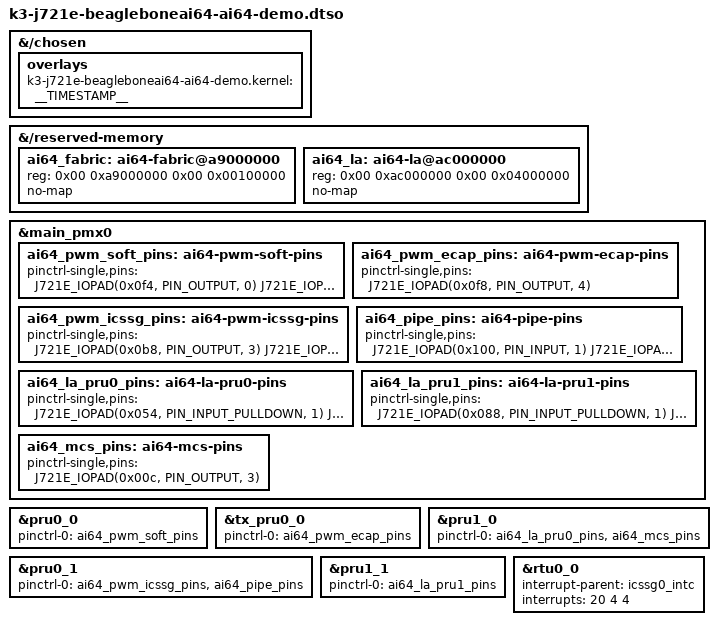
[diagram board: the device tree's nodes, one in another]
// SPDX-License-Identifier: MIT
// BeagleBone AI-64 demo: the ICSSG pins, the vring IRQ of ICSSG0 RTU0 (the
// RTU with RPMsg), and the DDR the cores use to talk to each other.
//
//   ICSSG0 slice 0, PWM in software (pru/pwm):
//     PRU0  P8.11  AB24  pad 0x0f4  mode 0  PRG0_PRU0_GPO17, output A
//     PRU0  P8.12  AH28  pad 0x0f0  mode 0  PRG0_PRU0_GPO16, output B
//     Tx_PRU0  P8.15  AB29  pad 0x0f8  mode 4  PRG0_ECAP0_IN_APWM_OUT, A's copy
//   ICSSG0 slice 1, the ICSSG's PWM module (pru/pwm):
//     PRU1  P9.12  AE27  pad 0x0b8  mode 3  PRG0_PWM2_A0, output A
//     PRU1  P9.15  AD25  pad 0x0c0  mode 3  PRG0_PWM2_B0, output B
//     PRU1  P8.31  AE29  pad 0x100  mode 1  PRG0_PRU1_GPI0, the pipeline's
//           input (zephyr/include/ai64_pipe.h); P8.31's other ball, AJ25
//           (pad 0x084), is held off: mode 7, transmit disabled
//   ICSSG1, the logic analyzer (pru/logic_analyzer): 19 inputs, each mode 1,
//     PRG1_PRU<n>_GPI<bit>, with its pull-down on (zephyr/include/ai64_la.h):
//     PRU0  P8.03 P8.07 P8.08 P8.09 P8.10 P8.36 P8.38 P9.11 P9.13 P9.23
//     PRU1  P8.05 P8.06 P8.21 P8.23 P8.25 P8.32 P8.33 P8.35 P9.21
//     P8.32, P8.33, P8.35, P8.38, and P9.21 have a second ball, held off
//   ICSSG1, the multicore scheduler (extra-demos/icssg1-multicore-scheduler):
//     all six cores  P8.17  AF22  pad 0x00c  mode 3  PRG1_PWM2_A0
//   The other header pins have one ball each.
//
// Zephyr muxes its own pins (UART2 on P8.34/P8.22, SPI7 on P9.28/P9.30/
// P9.31, EHRPWM4_B on P9.25) from its devicetree. They are not in this
// overlay. PINMUX.md lists every pin the demo uses.
//
// This overlay replaces k3-j721e-beagleboneai64-pwm-epwm4-p9_25.dtbo, which
// gives EHRPWM4 and the W26 ball to Linux; in this demo Zephyr owns both.
// install-beagle.sh drops that one from the boot entry.

/dts-v1/;
/plugin/;

#include "ti/k3-pinctrl.h"

&{/chosen} {
	overlays {
		k3-j721e-beagleboneai64-ai64-demo.kernel = __TIMESTAMP__;
	};
};

/*
 * The fabric (zephyr/include/ai64_fabric.h): every demo core's inbox, in
 * the 16 MiB gap between the C7x's carveout and the IPC region above it.
 * Linux must not use it, and maps it only through /dev/mem (ai64 fabric).
 */
&{/reserved-memory} {
	ai64_fabric: ai64-fabric@a9000000 {
		reg = <0x00 0xa9000000 0x00 0x00100000>;
		no-map;
	};

	/* The logic analyzer's two rings (zephyr/include/ai64_la.h). */
	ai64_la: ai64-la@ac000000 {
		reg = <0x00 0xac000000 0x00 0x04000000>;
		no-map;
	};
};

&main_pmx0 {
	ai64_pwm_soft_pins: ai64-pwm-soft-pins {
		pinctrl-single,pins = <
			J721E_IOPAD(0x0f4, PIN_OUTPUT, 0) /* (AB24) P8.11 PRG0_PRU0_GPO17 */
			J721E_IOPAD(0x0f0, PIN_OUTPUT, 0) /* (AH28) P8.12 PRG0_PRU0_GPO16 */
		>;
	};

	ai64_pwm_ecap_pins: ai64-pwm-ecap-pins {
		pinctrl-single,pins = <
			J721E_IOPAD(0x0f8, PIN_OUTPUT, 4) /* (AB29) P8.15 PRG0_ECAP0_IN_APWM_OUT */
		>;
	};

	ai64_pwm_icssg_pins: ai64-pwm-icssg-pins {
		pinctrl-single,pins = <
			J721E_IOPAD(0x0b8, PIN_OUTPUT, 3) /* (AE27) P9.12 PRG0_PWM2_A0 */
			J721E_IOPAD(0x0c0, PIN_OUTPUT, 3) /* (AD25) P9.15 PRG0_PWM2_B0 */
		>;
	};

	ai64_pipe_pins: ai64-pipe-pins {
		pinctrl-single,pins = <
			J721E_IOPAD(0x100, PIN_INPUT, 1) /* (AE29) P8.31 PRG0_PRU1_GPI0 */
			J721E_IOPAD(0x084, PIN_DISABLE, 7) /* (AJ25) P8.31, held off */
		>;
	};

	ai64_la_pru0_pins: ai64-la-pru0-pins {
		pinctrl-single,pins = <
			J721E_IOPAD(0x054, PIN_INPUT_PULLDOWN, 1) /* (AH21) P8.03 PRG1_PRU0_GPI19, ch0 */
			J721E_IOPAD(0x03c, PIN_INPUT_PULLDOWN, 1) /* (AD24) P8.07 PRG1_PRU0_GPI14, ch3 */
			J721E_IOPAD(0x038, PIN_INPUT_PULLDOWN, 1) /* (AG24) P8.08 PRG1_PRU0_GPI13, ch4 */
			J721E_IOPAD(0x044, PIN_INPUT_PULLDOWN, 1) /* (AE24) P8.09 PRG1_PRU0_GPI16, ch5 */
			J721E_IOPAD(0x040, PIN_INPUT_PULLDOWN, 1) /* (AC24) P8.10 PRG1_PRU0_GPI15, ch6 */
			J721E_IOPAD(0x020, PIN_INPUT_PULLDOWN, 1) /* (AE20) P8.36 PRG1_PRU0_GPI7, ch13 */
			J721E_IOPAD(0x024, PIN_INPUT_PULLDOWN, 1) /* (AJ20) P8.38 PRG1_PRU0_GPI8, ch14 */
			J721E_IOPAD(0x1a8, PIN_DISABLE, 7) /* (Y29) P8.38, held off */
			J721E_IOPAD(0x004, PIN_INPUT_PULLDOWN, 1) /* (AC23) P9.11 PRG1_PRU0_GPI0, ch15 */
			J721E_IOPAD(0x008, PIN_INPUT_PULLDOWN, 1) /* (AG22) P9.13 PRG1_PRU0_GPI1, ch16 */
			J721E_IOPAD(0x028, PIN_INPUT_PULLDOWN, 1) /* (AG20) P9.23 PRG1_PRU0_GPI9, ch18 */
		>;
	};

	ai64_la_pru1_pins: ai64-la-pru1-pins {
		pinctrl-single,pins = <
			J721E_IOPAD(0x088, PIN_INPUT_PULLDOWN, 1) /* (AH25) P8.05 PRG1_PRU1_GPI12, ch1 */
			J721E_IOPAD(0x08c, PIN_INPUT_PULLDOWN, 1) /* (AG25) P8.06 PRG1_PRU1_GPI13, ch2 */
			J721E_IOPAD(0x07c, PIN_INPUT_PULLDOWN, 1) /* (AF21) P8.21 PRG1_PRU1_GPI9, ch7 */
			J721E_IOPAD(0x080, PIN_INPUT_PULLDOWN, 1) /* (AB23) P8.23 PRG1_PRU1_GPI10, ch8 */
			J721E_IOPAD(0x090, PIN_INPUT_PULLDOWN, 1) /* (AH26) P8.25 PRG1_PRU1_GPI14, ch9 */
			J721E_IOPAD(0x06c, PIN_INPUT_PULLDOWN, 1) /* (AG21) P8.32 PRG1_PRU1_GPI5, ch10 */
			J721E_IOPAD(0x104, PIN_DISABLE, 7) /* (AD28) P8.32, held off */
			J721E_IOPAD(0x068, PIN_INPUT_PULLDOWN, 1) /* (AH24) P8.33 PRG1_PRU1_GPI4, ch11 */
			J721E_IOPAD(0x1c0, PIN_DISABLE, 7) /* (AA2) P8.33, held off */
			J721E_IOPAD(0x064, PIN_INPUT_PULLDOWN, 1) /* (AD23) P8.35 PRG1_PRU1_GPI3, ch12 */
			J721E_IOPAD(0x1d4, PIN_DISABLE, 7) /* (Y3) P8.35, held off */
			J721E_IOPAD(0x0a0, PIN_INPUT_PULLDOWN, 1) /* (AJ22) P9.21 PRG1_PRU1_GPI18, ch17 */
			J721E_IOPAD(0x16c, PIN_DISABLE, 7) /* (U28) P9.21, held off */
		>;
	};

	ai64_mcs_pins: ai64-mcs-pins {
		pinctrl-single,pins = <
			J721E_IOPAD(0x00c, PIN_OUTPUT, 3) /* (AF22) P8.17 PRG1_PWM2_A0 */
		>;
	};
};

/*
 * Each pad goes with the core that drives it, or that runs the ICSSG PWM
 * module behind it, and pru_rproc applies it when the core probes.
 */
&pru0_0 {
	pinctrl-names = "default";
	pinctrl-0 = <&ai64_pwm_soft_pins>;
};

/* Tx_PRU0 runs eCAP0. */
&tx_pru0_0 {
	pinctrl-names = "default";
	pinctrl-0 = <&ai64_pwm_ecap_pins>;
};

/* PRU1 runs the PWM module, and samples P8.31. */
&pru0_1 {
	pinctrl-names = "default";
	pinctrl-0 = <&ai64_pwm_icssg_pins>, <&ai64_pipe_pins>;
};

/*
 * ICSSG1's PRUs sample the analyzer's pins. With the multicore scheduler
 * loaded instead, PRU0 sets it up, and all six cores write P8.17's state.
 */
&pru1_0 {
	pinctrl-names = "default";
	pinctrl-0 = <&ai64_la_pru0_pins>, <&ai64_mcs_pins>;
};

&pru1_1 {
	pinctrl-names = "default";
	pinctrl-0 = <&ai64_la_pru1_pins>;
};

/*
 * RTU0's RPMsg: system event 20 (RTU0 to Linux) through channel 4 to host
 * interrupt 4, which reaches the A72. The 6.18 J721E tree has no vring
 * interrupt for any ICSSG core, and pru_rproc needs one for a core with RPMsg.
 */
&rtu0_0 {
	interrupt-parent = <&icssg0_intc>;
	interrupts = <20 4 4>;
	interrupt-names = "vring";
};
